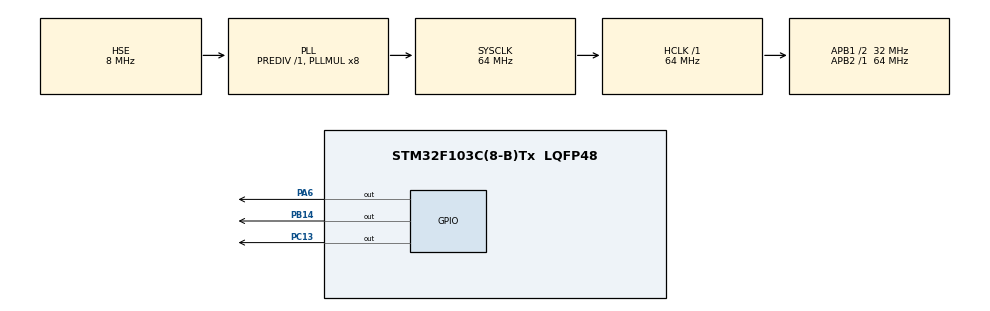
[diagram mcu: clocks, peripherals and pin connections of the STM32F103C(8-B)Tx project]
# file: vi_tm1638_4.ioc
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Mcu.Family=STM32F1
Mcu.Name=STM32F103C(8-B)Tx
Mcu.Package=LQFP48
NVIC.PriorityGroup=NVIC_PRIORITYGROUP_4
PA13.Mode=Serial_Wire
PA13.Signal=SYS_JTMS-SWDIO
PA14.Mode=Serial_Wire
PA14.Signal=SYS_JTCK-SWCLK
PA6.Signal=GPIO_Output
PB14.Signal=GPIO_Output
PC13-TAMPER-RTC.Signal=GPIO_Output
PD0-OSC_IN.Mode=HSE-External-Oscillator
PD0-OSC_IN.Signal=RCC_OSC_IN
PD1-OSC_OUT.Mode=HSE-External-Oscillator
PD1-OSC_OUT.Signal=RCC_OSC_OUT
ProjectManager.HeapSize=0x200
ProjectManager.StackSize=0x400
ProjectManager.TargetToolchain=STM32CubeIDE
RCC.AHBFreq_Value=64000000
RCC.APB1CLKDivider=RCC_HCLK_DIV2
RCC.APB1Freq_Value=32000000
RCC.APB1TimFreq_Value=64000000
RCC.APB2Freq_Value=64000000
RCC.APB2TimFreq_Value=64000000
RCC.HCLKFreq_Value=64000000
RCC.PLLMUL=RCC_PLL_MUL8
RCC.PLLSourceVirtual=RCC_PLLSOURCE_HSE
RCC.SYSCLKFreq_VALUE=64000000
RCC.SYSCLKSource=RCC_SYSCLKSOURCE_PLLCLK
RCC.USBFreq_Value=64000000
board=custom

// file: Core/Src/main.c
/* USER CODE BEGIN Header */
/**
  ******************************************************************************
  * @file           : main.c
  * @brief          : Main program body
  ******************************************************************************
  * @attention
  *
  * Copyright (c) 2023 STMicroelectronics.
  * All rights reserved.
  *
  * This software is licensed under terms that can be found in the LICENSE file
  * in the root directory of this software component.
  * If no LICENSE file comes with this software, it is provided AS-IS.
  *
  ******************************************************************************
  */
/* USER CODE END Header */
#include "main.h"

/* USER CODE BEGIN Includes */
#include <stdio.h>
#include "TM1638.h"
#include "TM1638_platform.h"
#include "Button_Config.h"
/* USER CODE END Includes */

/* USER CODE BEGIN PD */
//#define toggle(a) {a=a^1;}
/* USER CODE END PD */

void SystemClock_Config(void);
static void MX_GPIO_Init(void);

int main(void)
{

  /* MCU Configuration--------------------------------------------------------*/

  /* Reset of all peripherals, Initializes the Flash interface and the Systick. */
  HAL_Init();

  /* Configure the system clock */
  SystemClock_Config();

  /* Initialize all configured peripherals */
  MX_GPIO_Init();
  /* USER CODE BEGIN 2 */
  TM1638_Handler_t Handler;

  	  TM1638_Platform_Init(&Handler);
  	 TM1638_Init(&Handler, TM1638DisplayTypeComCathode);
  	//TM1638_Init(&Handler,TM1638DisplayTypeComAnode);
  	  TM1638_ConfigDisplay(&Handler, 1, TM1638DisplayStateOFF);
  	  HAL_Delay(100);
  	TM1638_ConfigDisplay(&Handler, 7, TM1638DisplayStateON);
  	 TM1638_SetSingleDigit_HEX(&Handler, 0, 2);
  		     HAL_Delay(100);
  		     TM1638_SetSingleDigit_HEX(&Handler, 0, 4);
 //uint8_t d=112;
  	 uint8_t i=0;
  	uint32_t keys = 0;//,sw1,sw2,sw3,sw4,sw5,sw6,sw7;
  	int status =0;

  /* USER CODE END 2 */
  	TM1638_SetSingleDigit_HEX(&Handler, 0, 0);
  /* Infinite loop */
  while (1)
  {

    /* USER CODE BEGIN 3 */
	 //  for (i = 0; i < 9; i++) {

	     HAL_Delay(100);
	     status = TM1638_ScanKeys(&Handler,&keys);

	     if (status == 0) {
	         switch (keys) {
	             case R_F :
	            	 ReverseForward();
	                 //TM1638_SetSingleDigit_HEX(&Handler, 1, 0);
	                 break;
	             case DECREMENT :
	            	 	 	// bar_led_status();
	      		     HAL_Delay(100);

	            	 HAL_GPIO_TogglePin(GPIOC, LED_PIN);
	            	 	            	// TM1638_SetSingleDigit_HEX(&Handler, i++, 0);
	            	 	            	 //if(i==10) i=0;
	                // i++;
	                 break;
	             case START_STOP:
	            	 StartMachine();
	                 //TM1638_SetSingleDigit_HEX(&Handler, 4, 0);
	                 break;
	             case INCREMENT:
	            	// bar_led_status();

	                 //TM1638_SetSingleDigit_HEX(&Handler, 1, 0);
	                 break;
	             case ULTRA_SELECT:
	            	 UltraSelect();
	                 //TM1638_SetSingleDigit_HEX(&Handler, 5, 0);
	                 break;
	             case MOTOR_SELECT:
	            	 MotorSelect();
	                 //TM1638_SetSingleDigit_HEX(&Handler, 6, 0);
	                 break;
	             case BLANK:
	                 //TM1638_SetSingleDigit_HEX(&Handler, 7, 0);
	                 break;
	             default:
	                 // Handle other cases if needed
	                 break;
	         }
	     }
	  	HAL_Delay(100);
	//  }
  }
  TM1638_DeInit(&Handler);
    return 0;
  /* USER CODE END 3 */
}

void SystemClock_Config(void)
{
  RCC_OscInitTypeDef RCC_OscInitStruct = {0};
  RCC_ClkInitTypeDef RCC_ClkInitStruct = {0};

  /** Initializes the RCC Oscillators according to the specified parameters
  * in the RCC_OscInitTypeDef structure.
  */
  RCC_OscInitStruct.OscillatorType = RCC_OSCILLATORTYPE_HSE;
  RCC_OscInitStruct.HSEState = RCC_HSE_ON;
  RCC_OscInitStruct.HSEPredivValue = RCC_HSE_PREDIV_DIV1;
  RCC_OscInitStruct.HSIState = RCC_HSI_ON;
  RCC_OscInitStruct.PLL.PLLState = RCC_PLL_ON;
  RCC_OscInitStruct.PLL.PLLSource = RCC_PLLSOURCE_HSE;
  RCC_OscInitStruct.PLL.PLLMUL = RCC_PLL_MUL8;
  if (HAL_RCC_OscConfig(&RCC_OscInitStruct) != HAL_OK)
  {
    Error_Handler();
  }

  /** Initializes the CPU, AHB and APB buses clocks
  */
  RCC_ClkInitStruct.ClockType = RCC_CLOCKTYPE_HCLK|RCC_CLOCKTYPE_SYSCLK
                              |RCC_CLOCKTYPE_PCLK1|RCC_CLOCKTYPE_PCLK2;
  RCC_ClkInitStruct.SYSCLKSource = RCC_SYSCLKSOURCE_PLLCLK;
  RCC_ClkInitStruct.AHBCLKDivider = RCC_SYSCLK_DIV1;
  RCC_ClkInitStruct.APB1CLKDivider = RCC_HCLK_DIV2;
  RCC_ClkInitStruct.APB2CLKDivider = RCC_HCLK_DIV1;

  if (HAL_RCC_ClockConfig(&RCC_ClkInitStruct, FLASH_LATENCY_2) != HAL_OK)
  {
    Error_Handler();
  }
}

static void MX_GPIO_Init(void)
{
  GPIO_InitTypeDef GPIO_InitStruct = {0};

  /* GPIO Ports Clock Enable */
  __HAL_RCC_GPIOC_CLK_ENABLE();
  __HAL_RCC_GPIOD_CLK_ENABLE();
  __HAL_RCC_GPIOA_CLK_ENABLE();
  __HAL_RCC_GPIOB_CLK_ENABLE();

  /*Configure GPIO pin Output Level */
  HAL_GPIO_WritePin(GPIOC, GPIO_PIN_13, GPIO_PIN_RESET);

  /*Configure GPIO pin Output Level */
  HAL_GPIO_WritePin(GPIOA, GPIO_PIN_6, GPIO_PIN_RESET);

  /*Configure GPIO pin Output Level */
  HAL_GPIO_WritePin(GPIOB, GPIO_PIN_14, GPIO_PIN_RESET);

  /*Configure GPIO pin : PC13 */
  GPIO_InitStruct.Pin = GPIO_PIN_13;
  GPIO_InitStruct.Mode = GPIO_MODE_OUTPUT_PP;
  GPIO_InitStruct.Pull = GPIO_NOPULL;
  GPIO_InitStruct.Speed = GPIO_SPEED_FREQ_LOW;
  HAL_GPIO_Init(GPIOC, &GPIO_InitStruct);

  /*Configure GPIO pin : PA6 */
  GPIO_InitStruct.Pin = GPIO_PIN_6;
  GPIO_InitStruct.Mode = GPIO_MODE_OUTPUT_PP;
  GPIO_InitStruct.Pull = GPIO_NOPULL;
  GPIO_InitStruct.Speed = GPIO_SPEED_FREQ_LOW;
  HAL_GPIO_Init(GPIOA, &GPIO_InitStruct);

  /*Configure GPIO pin : PB14 */
  GPIO_InitStruct.Pin = GPIO_PIN_14;
  GPIO_InitStruct.Mode = GPIO_MODE_OUTPUT_PP;
  GPIO_InitStruct.Pull = GPIO_NOPULL;
  GPIO_InitStruct.Speed = GPIO_SPEED_FREQ_LOW;
  HAL_GPIO_Init(GPIOB, &GPIO_InitStruct);

}

void Error_Handler(void)
{
  __disable_irq();
  while (1)
  {
  }
}
